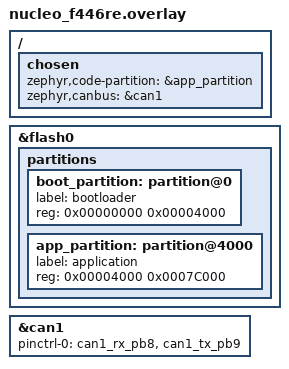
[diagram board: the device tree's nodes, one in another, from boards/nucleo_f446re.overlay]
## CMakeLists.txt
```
cmake_minimum_required(VERSION 3.20.0)

find_package(Zephyr REQUIRED HINTS $ENV{ZEPHYR_BASE})

project(user_application)

zephyr_get(CTRL_FRAME_ID SYSBUILD GLOBAL)

if(NOT "${CTRL_FRAME_ID}" MATCHES "^-?[0-9]+$")
    message(FATAL_ERROR "[User App] CTRL_FRAME_ID must be an integer, got '${CTRL_FRAME_ID}'")
endif()

add_compile_definitions(SYSBUILD_CTRL_FRAME_ID=${CTRL_FRAME_ID})

target_sources(app PRIVATE src/main.c)
```

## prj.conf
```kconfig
CONFIG_GPIO=y
CONFIG_CAN=y
CONFIG_LOG=y

# Bootloader requirements
CONFIG_REBOOT=y
CONFIG_FLASH_LOAD_OFFSET=0x8000
```

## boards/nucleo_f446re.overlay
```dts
/ {
    chosen {
        zephyr,code-partition = &app_partition;
        zephyr,canbus = &can1;
    };
};

// Placeholders
#define ENABLE_BOOTLOADER
#define DISABLE_TWO_SLOT_SOLUTION

#ifdef ENABLE_BOOTLOADER
&flash0 {
    partitions {
        // Remove in-tree MCUBoot
        /delete-node/ partition@10000;
        /delete-node/ partition@20000;
        /delete-node/ partition@40000;
        /delete-node/ partition@60000;

        // Custom Flash layout
        boot_partition: partition@0 {
            label = "bootloader";
            reg = <0x00000000 0x00004000>; // sector 0 (16 KB)
        };

        #ifdef DISABLE_TWO_SLOT_SOLUTION

        app_partition: partition@4000 {
            label = "application";
            reg = <0x00004000 0x0007C000>; // sectors 1 - 7 (496 KB)
        };

        #else

        app_partition: partition@4000 {
            label = "application";
            reg = <0x00004000 0x0003C000>; // sectors 1 - 5 (240 KB)
        };

        swap_partition: partition@40000 {
            label = "swap";
            reg = <0x00040000 0x00040000>; // sectors 6 - 7 (256 KB)
        };

        #endif
    };
};
#endif

&can1 {
	status = "okay";
    pinctrl-0 = < &can1_rx_pb8 &can1_tx_pb9 >;
    pinctrl-names = "default";
};
```

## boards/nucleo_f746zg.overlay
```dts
/ {
    chosen {
        zephyr,code-partition = &app_partition;
        zephyr,canbus = &can1;
    };
};

// Placeholders
#define ENABLE_BOOTLOADER
#define DISABLE_TWO_SLOT_SOLUTION

#ifdef ENABLE_BOOTLOADER
&flash0 {
	partitions {
		// Remove in-tree MCUBoot
        	/delete-node/ partition@20000;
		/delete-node/ partition@60000;
		/delete-node/ partition@80000;
		/delete-node/ partition@a0000;

		// Custom Flash layout
		boot_partition: partition@0 {
			label = "bootloader";
			reg = <0x00000000 0x00008000>; // sector 0 (32 KB)
		};

		#ifdef DISABLE_TWO_SLOT_SOLUTION

		app_partition: partition@8000 {
			label = "application";
			reg = <0x00008000 0x000F8000>; // sectors 1 - 7 (992 KB)
		};

		#else

		app_partition: partition@8000 {
			label = "application";
			reg = <0x00008000 0x00078000>; // sectors 1 - 5 (480 KB)
		};

		swap_partition: partition@80000 {
			label = "swap";
			reg = <0x00080000 0x00080000>;
		};

		#endif
	};
};
#endif

&can1 {
    status = "okay";
    pinctrl-0 = < &can1_rx_pd0 &can1_tx_pd1 >;
    pinctrl-names = "default";
};
```

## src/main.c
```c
#include <zephyr/kernel.h>
#include <zephyr/drivers/gpio.h>
#include <zephyr/drivers/can.h>
#include <zephyr/logging/log.h>
#include <zephyr/sys/reboot.h>

LOG_MODULE_REGISTER(Main, LOG_LEVEL_INF);

#define CAN_FRAME_BOOTLOADER_CTRL_ID SYSBUILD_CTRL_FRAME_ID
#define BOOTLOADER_COMMAND_START     0x0

static const struct gpio_dt_spec led0 = GPIO_DT_SPEC_GET(DT_ALIAS(led0), gpios);
static const struct gpio_dt_spec led2 = GPIO_DT_SPEC_GET(DT_ALIAS(led2), gpios);
static const struct device *can1      = DEVICE_DT_GET(DT_CHOSEN(zephyr_canbus));

static volatile bool bootloader_flag = 0;

static int gpio_setup();
static int can_setup();

static void rx_callback(const struct device *dev, struct can_frame *frame, void *user_data) 
{
    if (frame->id != CAN_FRAME_BOOTLOADER_CTRL_ID) {
        return;
    }

    if (frame->dlc != 1) {
        return;
    }

    if (frame->data[0] != BOOTLOADER_COMMAND_START) {
        return;
    }

    bootloader_flag = 1;
}

int main()
{
    int ret;

    ret = gpio_setup();
    if (ret < 0) {
        LOG_ERR("GPIO setup failed, error %d", ret);
        return ret;
    }

    ret = can_setup();
    if (ret < 0) {
        LOG_ERR("CAN setup failed, error %d", ret);
        return ret;
    }

    while (1) {
        if (bootloader_flag) {
            sys_reboot(SYS_REBOOT_COLD);
        }

        gpio_pin_toggle_dt(&led0);
        gpio_pin_toggle_dt(&led2);
        k_sleep(K_MSEC(1000));
    }

    return 0;
}

static int gpio_setup()
{
    int ret;

    if (!device_is_ready(led0.port)) {
        LOG_ERR("led0 not ready");
        return -1;
    }

    if (!device_is_ready(led2.port)) {
        LOG_ERR("led2 not ready");
        return -1;
    }

    ret = gpio_pin_configure_dt(&led0, GPIO_OUTPUT_INACTIVE);
    if (ret < 0) {
        LOG_ERR("Failed to configure led0, error %d", ret);
        return ret;
    }

    ret = gpio_pin_configure_dt(&led2, GPIO_OUTPUT_INACTIVE);
    if (ret < 0) {
        LOG_ERR("Failed to configure led2, error %d", ret);
        return ret;
    }

    return 0;
}

static int can_setup()
{
    if (!device_is_ready(can1)) {
        LOG_ERR("can1 not ready");
        return -1;
    }

    struct can_filter filter = {
        .id    = 0x0,
        .mask  = 0x0,
        .flags = 0x0
    };

    int ret = can_add_rx_filter(can1, &rx_callback, NULL, &filter);
    if (ret < 0) {
        LOG_ERR("Failed to set CAN filter, error %d", ret);
        return ret;
    }

    return can_start(can1);
}
```
